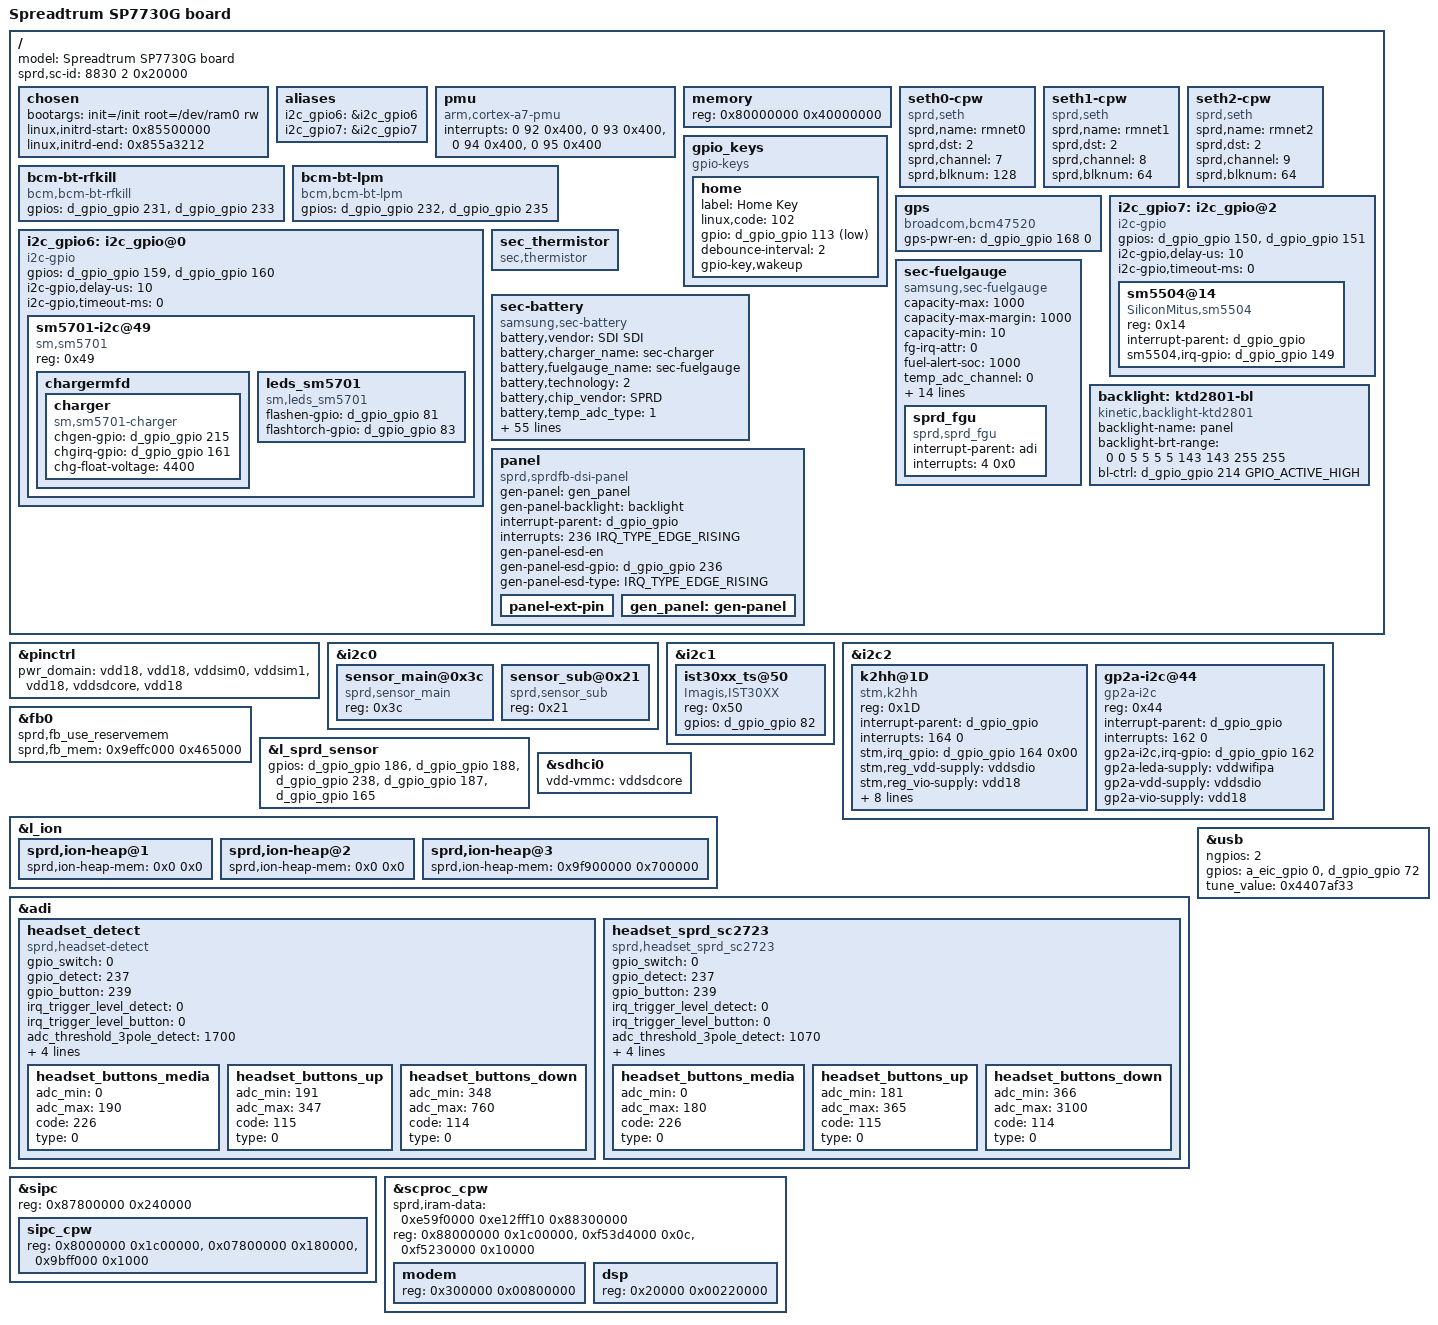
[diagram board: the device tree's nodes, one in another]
/*
 * Copyright (C) 2013 Spreadtrum Communication Incorporated
 *		http://www.spreadtrum.com/
 *
 * This program is free software; you can redistribute it and/or modify
 * it under the terms of the GNU General Public License version 2 as
 * published by the Free Software Foundation.
 */
/dts-v1/;

/* memory reserved for SMEM */
/memreserve/ 0x87800000 0x240000; /* 2MK+256K */

/* memory reserved for CPW modem */
/memreserve/ 0x88000000 0x1c00000; /* 28M */

/* memory reserved for fb */
/memreserve/ 0x9effc000 0x465000; /* 4,608 Kb */

/* memory reserved for ION */
/memreserve/ 0x9f5fc000 0xa04000; /* 7MK */

/include/ "sprd-scx35.dtsi"
/include/ "sprd-scx35_sc7730.dtsi"
#include <dt-bindings/gpio/gpio.h>
#include <dt-bindings/video/gen-panel.h>
#include <dt-bindings/interrupt-controller/irq.h>

/ {
	model = "Spreadtrum SP7730G board";
        sprd,sc-id = <8830 2 0x20000>;
	chosen {
		bootargs = "init=/init root=/dev/ram0 rw";
		linux,initrd-start = <0x85500000>;
		linux,initrd-end   = <0x855a3212>;
	};

	aliases {
		i2c_gpio6 = &i2c_gpio6;
		i2c_gpio7 = &i2c_gpio7;
		/*i2c_gpio8 = &i2c_gpio8;*/
	};

	pmu {
		compatible = "arm,cortex-a7-pmu";
		interrupts = <0 92 0x400>,
		<0 93 0x400>,
		<0 94 0x400>,
		<0 95 0x400>;
	};

	memory {
		device_type = "memory";
		reg = <0x80000000 0x40000000>;
	};

    // seth_w -> rmnet
	seth0-cpw {
		compatible = "sprd,seth";
		sprd,name = "rmnet0";
		sprd,dst = <2>;
		sprd,channel = <7>;
		sprd,blknum = <128>;
	};

	seth1-cpw {
		compatible = "sprd,seth";
		sprd,name = "rmnet1";
		sprd,dst = <2>;
		sprd,channel = <8>;
		sprd,blknum = <64>;
	};

	seth2-cpw {
		compatible = "sprd,seth";
		sprd,name = "rmnet2";
		sprd,dst = <2>;
		sprd,channel = <9>;
		sprd,blknum = <64>;
	};

	gpio_keys {
		compatible = "gpio-keys";
		home {
			label = "Home Key";
			linux,code = <102>;
			gpio = <&d_gpio_gpio 113 1>;
			debounce-interval = <2>;
			gpio-key,wakeup;
		};
	};

	bcm-bt-rfkill {
		compatible = "bcm,bcm-bt-rfkill";
		gpios = <&d_gpio_gpio 231 0  /* power */
				&d_gpio_gpio 233 0>;  /* reset */
	};

	bcm-bt-lpm {
		compatible = "bcm,bcm-bt-lpm";
		gpios = <&d_gpio_gpio 232 0  /* bt_wake */
                        &d_gpio_gpio 235 0>;  /* bt_host_wake */
	};

	gps {
		compatible = "broadcom,bcm47520";
		gps-pwr-en = <&d_gpio_gpio 168 0>; /*GPS_PWON*/
	};

	i2c_gpio6: i2c_gpio@0 {
		compatible = "i2c-gpio";
		#address-cells = <1>;
		#size-cells = <0>;
		gpios = <&d_gpio_gpio 159 0 /* sda */
                        &d_gpio_gpio 160 0 >; /* scl */
		i2c-gpio,delay-us = <10>;    /* ~100 kHz */
		i2c-gpio,timeout-ms = <0>;

		sm5701-i2c@49 {
			compatible = "sm,sm5701";
			reg = <0x49>;
			chargermfd {
				charger {
					compatible = "sm,sm5701-charger";
					chgen-gpio = <&d_gpio_gpio 215 0>;
					chgirq-gpio = <&d_gpio_gpio 161 0>;
					chg-float-voltage = <4400>;
				};
			};
                        leds_sm5701 {
                                        compatible = "sm,leds_sm5701";
                                        flashen-gpio = <&d_gpio_gpio 81 0>;
                                        flashtorch-gpio = <&d_gpio_gpio 83 0>;
                        };

		};
	};

	i2c_gpio7: i2c_gpio@2 {
		compatible = "i2c-gpio";
		#address-cells = <1>;
		#size-cells = <0>;
		gpios = <&d_gpio_gpio 150 0 /* sda */
                        &d_gpio_gpio 151 0 >; /* scl */
		i2c-gpio,delay-us = <10>;    /* ~100 kHz */
		i2c-gpio,timeout-ms = <0>;

		sm5504@14 {
			compatible = "SiliconMitus,sm5504";
			reg = <0x14>;
			interrupt-parent = <&d_gpio_gpio>;
			sm5504,irq-gpio = <&d_gpio_gpio 149 0>;
		};
	};

	sec_thermistor {
		compatible = "sec,thermistor";
	};

	sec-fuelgauge {
		compatible = "samsung,sec-fuelgauge";
		capacity-max = <1000>;
		capacity-max-margin = <1000>;
		capacity-min = <10>;
		fg-irq-attr = <0>;
		fuel-alert-soc = <1000>;
		temp_adc_channel = <0>;
		chg_bat_safety_vol = <4600>;
		gpios = <&a_eic_gpio 0 0>;/* chg int */
		soft_vbat_uvlo = <3050>;
		vmode = <0>; /* 1=Voltage mode, 0=mixed mode */
		alm_soc = <5>; /* SOC alm level %*/
		alm_vbat = <3500>; /* Vbat alm level mV*/
		rint = <200>; /*battery internal impedance*/
		cnom = <2000>; /* nominal capacity in mAh */
		rsense_real = <210>; /* sense resistor 0.1mOhm from real environment*/
		rsense_spec = <200>; /* sense resistor 0.1mOhm from specification*/
		relax_current = <50>; /* current for relaxation in mA (< C/20) */
		cal_ajust = <0>; /* ajust calibration data */
		ocv_table = <4370 100
					4332 95
					4277 90
					4221 85
					4166 80
					4113 75
					4063 70
					4018 65
					3977 60
					3933 55
					3881 50
					3850 45
					3826 40
					3807 35
					3791 30
					3778 25
					3762 20
					3742 15
					3711 10
					3683 5
					3400 0>;
		sprd_fgu: sprd_fgu{
			compatible  = "sprd,sprd_fgu";
			interrupt-parent = <&adi>;
			interrupts = <4 0x0>;
		};
	};

	sec-battery {
		compatible = "samsung,sec-battery";
		battery,vendor = "SDI SDI";
		battery,charger_name = "sec-charger";
		battery,fuelgauge_name = "sec-fuelgauge";
		battery,technology = <2>; /* POWER_SUPPLY_TECHNOLOGY_LION */

		battery,chip_vendor = "SPRD";
		battery,temp_adc_type = <1>; /* SEC_BATTERY_ADC_TYPE_AP */

		battery,polling_time = <10 30 30 30 3600>;

		battery,adc_check_count = <5>;

		battery,cable_check_type = <5>; /* SEC_BATTERY_CABLE_CHECK_PSY */
		battery,cable_source_type = <3>; /* SEC_BATTERY_CABLE_SOURCE_EXTERNAL */
		battery,event_waiting_time = <600>;
		battery,polling_type = <1>; /* SEC_BATTERY_MONITOR_ALARM */
		battery,monitor_initial_count = <3>;

		battery,battery_check_type = <5>; /* SEC_BATTERY_CHECK_CHARGER */
		battery,check_count = <0>;
		battery,check_adc_max = <1440>;
		battery,check_adc_min = <0>;

		battery,ovp_uvlo_check_type = <4>; /* SEC_BATTERY_OVP_UVLO_CHGINT */

		battery,thermal_source = <2>; /* SEC_BATTERY_THERMAL_SOURCE_ADC */

		battery,temp_table_adc = <501 615 738 795 846 956 1065 1088 1180 1307 1392 1477 1627 1777 1922 2098
			2144 2182 2212 2260 2302 2452 2555>;
		battery,temp_table_data = <700 650 600 580 550 500 460 450 400 350 300 250 200 150 100
			50 20 0 (-20) (-50) (-70) (-150) (-200)>;

		battery,temp_check_type = <2>; /* SEC_BATTERY_TEMP_CHECK_TEMP */
		battery,temp_check_count = <1>;
		battery,temp_high_threshold_event = <600>;
		battery,temp_high_recovery_event = <460>;
		battery,temp_low_threshold_event = <(-50)>;
		battery,temp_low_recovery_event = <0>;
		battery,temp_high_threshold_normal = <600>;
		battery,temp_high_recovery_normal = <460>;
		battery,temp_low_threshold_normal = <(-50)>;
		battery,temp_low_recovery_normal = <0>;
		battery,temp_high_threshold_lpm = <600>;
		battery,temp_high_recovery_lpm = <460>;
		battery,temp_low_threshold_lpm = <(-50)>;
		battery,temp_low_recovery_lpm = <0>;
		battery,full_check_type = <7>; /* SEC_BATTERY_FULLCHARGED_CHGPSY */
		battery,full_check_type_2nd = <3>; /* SEC_BATTERY_FULLCHARGED_TIME */
		battery,full_check_count = <1>;
		battery,chg_gpio_full_check = <0>;
		battery,chg_polarity_full_check = <1>;

		battery,full_condition_type = <13>;
		battery,full_condition_soc = <95>;
		battery,full_condition_vcell = <4200>;

		battery,recharge_check_count = <1>;
		battery,recharge_condition_type = <4>; /* SEC_BATTERY_RECHARGE_CONDITION_VCELL */
		battery,recharge_condition_soc = <95>;
		battery,recharge_condition_vcell = <4350>;

		battery,charging_total_time = <21600>;
		battery,recharging_total_time = <5400>;
		battery,charging_reset_time = <0>;

		/* Charger */
		charger,vbus_ctrl_gpio = <&d_gpio_gpio 64 0x00>;
		battery,input_current_limit = <700 460 460 700 460 700 700 460 460 700 700 700 700 460 700 300 700 700 300 700 700 460 460>;
		battery,fast_charging_current = <975 0 975 975 975 975 975 975 0 975 975 975 975 (-1) 975 975 975 975 975 975 975 0 0>;
		battery,full_check_current_1st = <175 0 175 175 175 175 175 175 0 175 175 175 175 0 175 175 175 175 175 175 175 0 0>;
		battery,full_check_current_2nd = <1800 0 1800 1800 1800 1800 1800 1800 0 1800 1800 1800 1800 0 1800 1800 1800 1800 1800 1800 1800 0 0>;
	};

	backlight: ktd2801-bl {
		compatible = "kinetic,backlight-ktd2801";
		backlight-name = "panel";
		backlight-brt-range = <
			0	0	/* OFF */
			5	5	/* MIN */
			5	5	/* DIM */
			143	143	/* DEF */
			255	255	/* MAX */
		>;
		bl-ctrl = <&d_gpio_gpio 214 GPIO_ACTIVE_HIGH>;
	};

	panel {
		compatible = "sprd,sprdfb-dsi-panel";
		pinctrl-names = "default";
		gen-panel = <&gen_panel>;
		gen-panel-backlight = <&backlight>;
		interrupt-parent = <&d_gpio_gpio>;
		interrupts = <236 IRQ_TYPE_EDGE_RISING>;
		gen-panel-esd-en;
		gen-panel-esd-gpio = <&d_gpio_gpio 236 GPIO_ACTIVE_HIGH>;
		gen-panel-esd-type = <IRQ_TYPE_EDGE_RISING>;
		panel-ext-pin {
			/*
			 * Three properties are required
			 * to control pwr pin
			 * @node : panel-ext-pin node
			 * @on : <0> - off / <1> - on
			 * @usec : delay time of usec
			 */
			/*
			 * There are four properties to define pwr pin
			 * pin-name : pin name
			 * pin-type : <0> - GPIO, <1> - PMIC Regulator
			 * pin-gpio : If the type is GPIO, assign a gpio.
			 * pin-supply : If the type is PMIC Regulator, assign a regulator.
			 */
		};
		gen_panel: gen-panel {};
	};
};

/include/ "sprd-dsi-panel-dsi_sc7798d_dtc_wVGA_video.dtsi"
/include/ "sprd-dsi-panel-dsi_sc7798d_wVGA_video.dtsi"
/include/ "sprd-dsi-panel-dsi_hx8369b_pls_wVGA_video.dtsi"
/include/ "sprd-dsi-panel-dsi_hx8369b_wVGA_video.dtsi"
/include/ "sprd-dsi-panel-dsi_nt35502_wVGA_video.dtsi"

&pinctrl {
	pwr_domain ="vdd18", /* "vdd28" */ /* VIO_2_0_ms */
				"vdd18", /* "vdd28" */ /* VIO_2_1_ms */
				"vddsim0",
				"vddsim1",
				"vdd18", /* "vddsim2" */
				"vddsdcore",
				"vdd18";
};

&i2c0 {
	sensor_main@0x3c {
		compatible = "sprd,sensor_main";
		reg = <0x3c>;
	};
	sensor_sub@0x21 {
		compatible = "sprd,sensor_sub";
		reg = <0x21>;
	};
};

&i2c1 { /* TSP */
	ist30xx_ts@50 {
		compatible = "Imagis,IST30XX";
		reg = <0x50>;
		gpios = <&d_gpio_gpio 82 0>;
	};
};

&i2c2 { /* Sensor */
	status = "okay";
	k2hh@1D {
		compatible = "stm,k2hh";
		reg = <0x1D>;
		interrupt-parent = <&d_gpio_gpio>;
		interrupts = <164 0>;
		stm,irq_gpio = <&d_gpio_gpio 164 0x00>;
		stm,reg_vdd-supply = <&vddsdio>;
		stm,reg_vio-supply = <&vdd18>;
		stm,axis_map_x = <0>;
		stm,axis_map_y = <1>;
		stm,axis_map_z = <2>;
		stm,negate_x = <0>;
		stm,negate_y = <1>;
		stm,negate_z = <0>;
		stm,poll_interval = <100>;
		stm,min_interval = <2>;
	};

	gp2a-i2c@44{
		compatible = "gp2a-i2c";
		reg = <0x44>;
		interrupt-parent = <&d_gpio_gpio>;
		interrupts= <162 0>;
		gp2a-i2c,irq-gpio = <&d_gpio_gpio 162 0x00>;
		gp2a-leda-supply = <&vddwifipa>;
		gp2a-vdd-supply = <&vddsdio>;
		gp2a-vio-supply = <&vdd18>;
	};
};

&fb0 {
	sprd,fb_use_reservemem;
	sprd,fb_mem = <0x9effc000 0x465000>;
};

&l_sprd_sensor {
	gpios = <&d_gpio_gpio 186 0           /*main reset*/
			&d_gpio_gpio 188 0    /*main power down*/
			&d_gpio_gpio 238 0    /*sub reset*/
			&d_gpio_gpio 187 0    /*sub power down*/
			&d_gpio_gpio 165 0>;  /*main dvdd en*/
};

&sdhci0 {
	vdd-vmmc = "vddsdcore";
	//vdd-vqmmc = "vddsdio";
	//sd-supply = <&vddsdio>;
};

&l_ion {
	sprd,ion-heap@1 {
		sprd,ion-heap-mem = <0x0 0x0>;
	};

	sprd,ion-heap@2 {
		sprd,ion-heap-mem = <0x0 0x0>;
	};

	sprd,ion-heap@3 {
		sprd,ion-heap-mem = <0x9f900000 0x700000>;
	};
};

&adi {
	headset_detect {
		compatible = "sprd,headset-detect";
		gpio_switch = <0>;
		gpio_detect = <237>;
		gpio_button = <239>;
		irq_trigger_level_detect = <0>;
		irq_trigger_level_button = <0>;
		adc_threshold_3pole_detect = <1700>;
		adc_threshold_4pole_detect = <2700>;
		irq_threshold_buttont = <1>;
		voltage_headmicbias = <3000000>;
		nbuttons = <3>;
		headset_buttons_media {
			adc_min = <0>;
			adc_max = <190>;
			code = <226>;
			type = <0>;
		};

		headset_buttons_up {
			adc_min = <191>;
			adc_max = <347>;
			code = <115>;
			type = <0>;
		};

		headset_buttons_down {
			adc_min = <348>;
			adc_max =<760>;
			code = <114>;
			type = <0>;
		};
	};

	headset_sprd_sc2723 {
		compatible = "sprd,headset_sprd_sc2723";
		gpio_switch = <0>;
		gpio_detect = <237>;
		gpio_button = <239>;
		irq_trigger_level_detect = <0>;
		irq_trigger_level_button = <0>;
		adc_threshold_3pole_detect = <1070>;
		adc_threshold_4pole_detect = <3100>;
		irq_threshold_buttont = <1>;
		voltage_headmicbias = <3000000>;
		nbuttons = <3>;
		headset_buttons_media {
			adc_min = <0>;
			adc_max = <180>;
			code = <226>;
			type = <0>;
		};

		headset_buttons_up {
			adc_min = <181>;
			adc_max = <365>;
			code = <115>;
			type = <0>;
		};

		headset_buttons_down {
			adc_min = <366>;
			adc_max =<3100>;
			code = <114>;
			type = <0>;
		};
	};
};

/* sipc initializer */
&sipc {
	reg = <0x87800000 0x240000>; /* <SMEM SIZE>*/
	ranges = <0x8000000 0x88000000 0x1c00000>,
			<0x07800000 0x87800000 0x180000>,
			<0x9bff000 0x89bff000 0x1000>;
	sipc_cpw {
		reg = <0x8000000 0x1c00000> , /* <CP_start_addr size> */
		<0x07800000 0x180000>, /* <SMEM_phy_addr total_size> */
		<0x9bff000 0x1000>; /* smsg ring buffer <base size> */
	};
};

&scproc_cpw {
	sprd,iram-data = <0xe59f0000 0xe12fff10 0x88300000>; /* 3rd param equals modem_addr*/
	reg = <0x88000000 0x1c00000>, /* <CP_start_addr total_size> = <+128M 28M> */
		<0xf53d4000 0x0c>, /* <iram1_base size> */
		<0xf5230000 0x10000>; /* <pmu_base size> */
	ranges = <0x300000 0x88300000 0x00800000>,
			<0x20000 0x88020000 0x00220000>;
	modem {
		reg = <0x300000 0x00800000>; /* <modem_addr size> */
	};
	dsp {
		reg = <0x20000 0x00220000>; /* <dsp_addr size>*/
	};
};

&usb{
	ngpios = <2>;
	gpios = <&a_eic_gpio 0 0>,<&d_gpio_gpio 72 0>;
	tune_value = <0x4407af33>;
};

